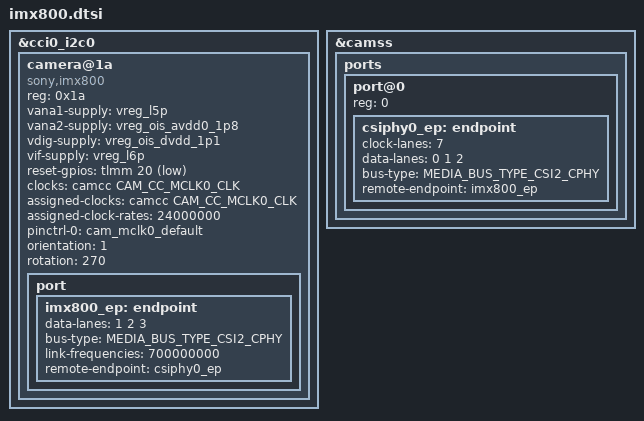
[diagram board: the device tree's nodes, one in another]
// SPDX-License-Identifier: GPL-2.0-only
/*
 * Fairphone 5 (qcm6490) — Sony IMX800 main rear camera + CSIPHY0 C-PHY.
 *
 * Merge into the board DTS (CCI0 bus 0). Supply / clock phandles must match
 * the board; names below follow the existing FP5 mainline DTS.
 */

&cci0_i2c0 {
	camera@1a {
		compatible = "sony,imx800";
		reg = <0x1a>;

		/* Power (Android cam-sensor0 mapping) */
		vana1-supply = <&vreg_l5p>;		/* ~2.8 V */
		vana2-supply = <&vreg_ois_avdd0_1p8>;	/* ~1.8 V */
		vdig-supply = <&vreg_ois_dvdd_1p1>;	/* ~1.1 V */
		vif-supply = <&vreg_l6p>;		/* ~1.8 V IO / CCI */

		reset-gpios = <&tlmm 20 GPIO_ACTIVE_LOW>; /* XCLR */

		clocks = <&camcc CAM_CC_MCLK0_CLK>;
		assigned-clocks = <&camcc CAM_CC_MCLK0_CLK>;
		assigned-clock-rates = <24000000>;
		pinctrl-0 = <&cam_mclk0_default>;
		pinctrl-names = "default";

		orientation = <1>;	/* rear */
		rotation = <270>;	/* degrees clockwise */
		status = "okay";

		port {
			imx800_ep: endpoint {
				data-lanes = <1 2 3>;
				bus-type = <MEDIA_BUS_TYPE_CSI2_CPHY>;
				link-frequencies = /bits/ 64 <700000000>;
				remote-endpoint = <&csiphy0_ep>;
			};
		};
	};
};

/* CSIPHY0 — free on FP5 mainline (port@1 = imx858, port@3 = s5kjn1) */
&camss {
	ports {
		port@0 {
			reg = <0>;
			csiphy0_ep: endpoint {
				clock-lanes = <7>;
				data-lanes = <0 1 2>;
				bus-type = <MEDIA_BUS_TYPE_CSI2_CPHY>;
				remote-endpoint = <&imx800_ep>;
			};
		};
	};
};
